# GD32G5x3 register map
File version: 1.0
CPU: CM33 r2p1, little endian, MPU, FPU, 4 interrupt priority bits
Registers are 32-bit, read-write, reset 0x0 unless marked. A register's access mark holds for its fields unless they carry their own. Offsets are from the block's base; [hi:lo] are bit positions; {n}, {i} and the like mark numbered series; 'fields as' and 'values as' point back to an identical list.

## DMAMUX — DMA request multiplexer
Base 0x40020800
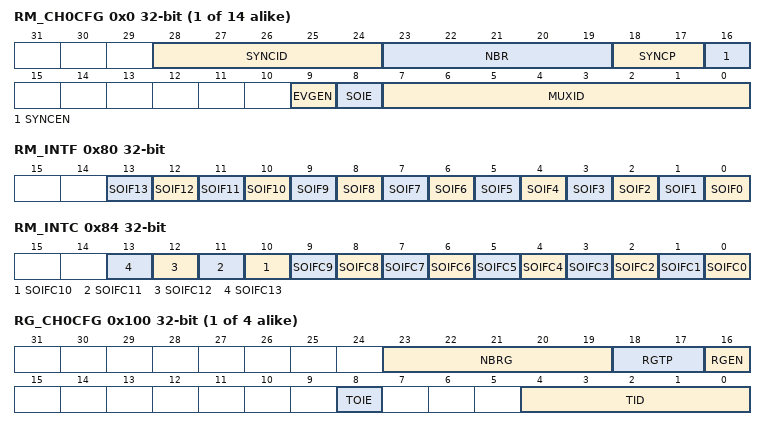
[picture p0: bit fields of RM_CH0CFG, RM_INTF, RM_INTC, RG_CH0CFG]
{0x0+4i} RM_CH{i}CFG (i=0..13) — Request multiplexer channel {i} configuration register
  [28:24] SYNCID — Synchronization input identification
  [23:19] NBR — Number of DMA requests to forward
  [18:17] SYNCP — Synchronization input polarity
  [16] SYNCEN — Synchronization enable
  [9] EVGEN — Event generation enable
  [8] SOIE — Synchronization overrun interrupt enable
  [7:0] MUXID — Multiplexer input identification
0x80 RM_INTF ro — Request multiplexer channel interrupt flag register
  [n] SOIF{n} (n=0..13) — Synchronization overrun event flag of request multiplexer channel {n}
0x84 RM_INTC wo — Request multiplexer channel interrupt flag clear register
  [n] SOIFC{n} (n=0..13) — Clear bit for synchronization overrun event flag of request multiplexer channel {n}
{0x100+4i} RG_CH{i}CFG (i=0..3) — Request generator channel {i} configuration register
  [23:19] NBRG — Number of DMA requests to be generated
  [18:17] RGTP — DMA request generator trigger polarity
  [16] RGEN — DMA request generator channel x enable
  [8] TOIE — Trigger overrun interrupt enable
  [4:0] TID — Trigger input identification
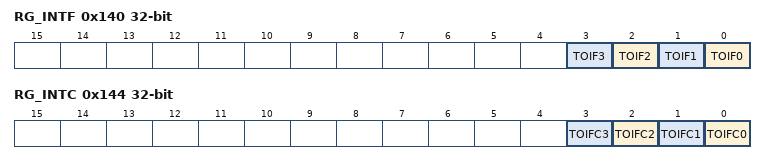
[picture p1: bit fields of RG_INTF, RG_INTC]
0x140 RG_INTF ro — Request generator interrupt flag register
  [n] TOIF{n} (n=0..3) — Trigger overrun event flag of request generator channel {n}
0x144 RG_INTC wo — Request generator interrupt flag clear register
  [n] TOIFC{n} (n=0..3) — Clear bit for trigger overrun event flag of request generator channel {n}

## EXMC — External memory controller
Base 0xA0000000
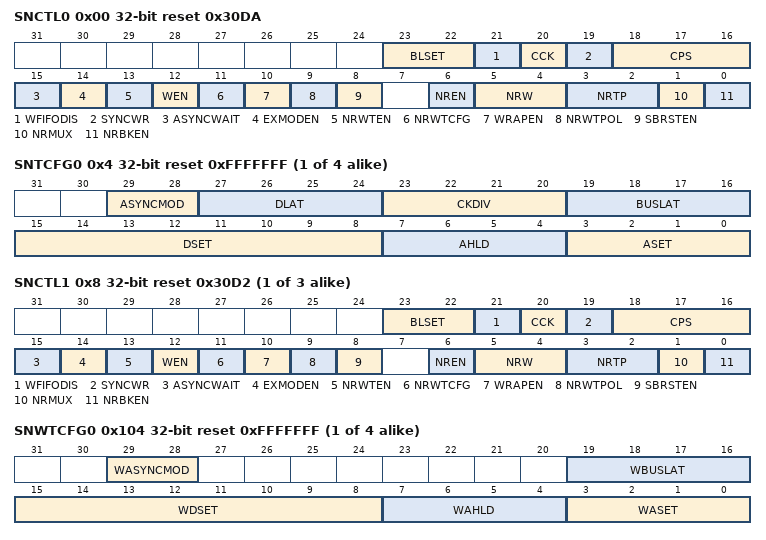
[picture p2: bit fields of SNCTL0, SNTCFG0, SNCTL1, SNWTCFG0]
0x00 SNCTL0 reset 0x30DA — SRAM/NOR Flash control registe 0
  [23:22] BLSET — NBL(Byte lane) setup time
  [21] WFIFODIS — Write FIFO disabled
  [20] CCK — Consecutive Clock
  [19] SYNCWR — Synchronous write
  [18:16] CPS — CRAM page size
  [15] ASYNCWAIT — Asynchronous wait
  [14] EXMODEN — Extended mode enable
  [13] NRWTEN — NWAIT signal enable
  [12] WEN — Write enable
  [11] NRWTCFG — NWAIT signal configuration, only work in synchronous mode
  [10] WRAPEN — Wrapped burst mode enable
  [9] NRWTPOL — NWAIT signal polarity
  [8] SBRSTEN — Synchronous burst enable
  [6] NREN — NOR Flash access enable
  [5:4] NRW — NOR region memory data bus width
  [3:2] NRTP — NOR region memory type
  [1] NRMUX — NOR region memory address/data multiplexing
  [0] NRBKEN — NOR region enable
{0x4+8i} SNTCFG{i} reset 0xFFFFFFF (i=0..3) — SRAM/NOR Flash timing configuration registe {i}
  [29:28] ASYNCMOD — Asynchronous access mode
  [27:24] DLAT — Data latency for NOR Flash
  [23:20] CKDIV — Synchronous clock divide ratio
  [19:16] BUSLAT — Bus latency
  [15:8] DSET — Data setup time
  [7:4] AHLD — Address hold time
  [3:0] ASET — Address setup time
{0x0+8i} SNCTL{i} reset 0x30D2 (i=1..3) — SRAM/NOR Flash control registe {i}
  fields as SNCTL0
0x84 SNSTAT ro reset 0x40 — SRAM/NOR flash status registers
  [6] FIFOEPT — FIFO empty flag
{0x104+8i} SNWTCFG{i} reset 0xFFFFFFF (i=0..3) — SRAM/NOR Flash write timing configuration registe {i}
  [29:28] WASYNCMOD — Asynchronous access mode
  [19:16] WBUSLAT — Bus latency
  [15:8] WDSET — Data setup time
  [7:4] WAHLD — Address hold time
  [3:0] WASET — Address setup time
{0x300+4i} SNLATDEC{i} (i=0..3) — SRAM/NOR flash data latency decrease register {i}
  [2:0] LATDEC — Data latency decrease for NOR Flash

## EXTI — External interrupt/event controller
Base 0x40010400
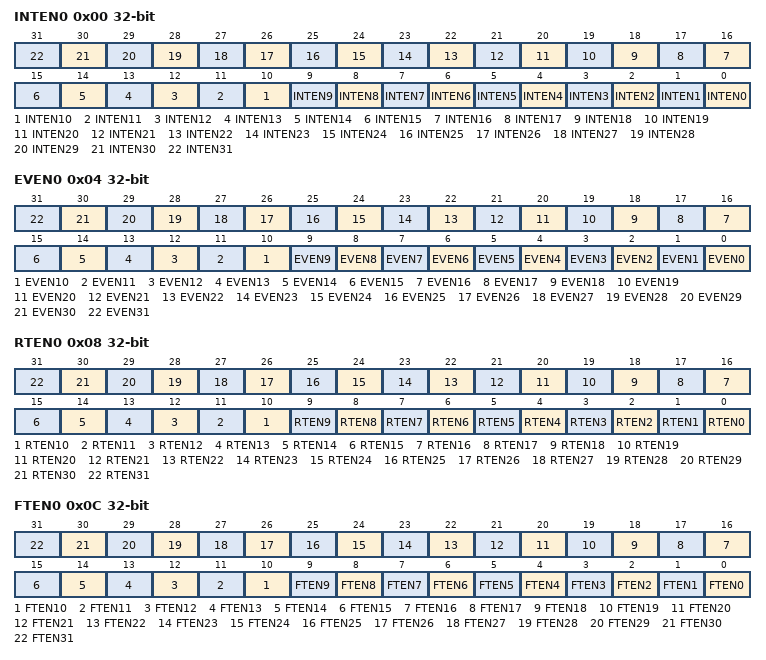
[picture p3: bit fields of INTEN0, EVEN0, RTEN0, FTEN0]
0x00 INTEN0 — Interrupt enable register 0
  [n] INTEN{n} (n=0..31) — Interrupt enable bit {n}
0x04 EVEN0 — Event enable register 0
  [n] EVEN{n} (n=0..31) — Event enable bit {n}
0x08 RTEN0 — Rising edge trigger enable register 0
  [n] RTEN{n} (n=0..31) — Rising edge trigger enable bit {n}
0x0C FTEN0 — Falling edge trigger enable register 0
  [n] FTEN{n} (n=0..31) — Falling edge trigger enable bit {n}
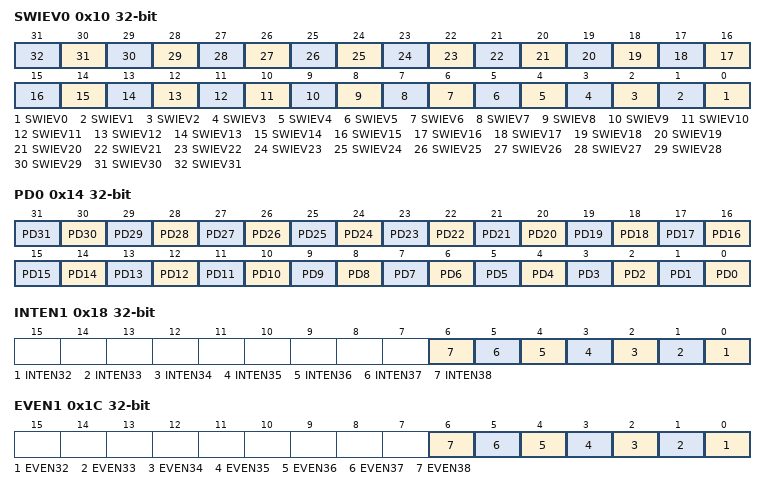
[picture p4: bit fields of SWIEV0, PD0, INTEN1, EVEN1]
0x10 SWIEV0 — Software interrupt event register 0
  [n] SWIEV{n} (n=0..31) — Interrupt/Event software trigger bit {n}
0x14 PD0 — Pending register 0
  [n] PD{n} (n=0..31) — Interrupt pending status bit {n}
0x18 INTEN1 — Interrupt enable register 1
  [n-32] INTEN{n} (n=32..38) — Interrupt enable bit {n-32}
0x1C EVEN1 — Event enable register 1
  [n-32] EVEN{n} (n=32..38) — Event enable bit {n-32}
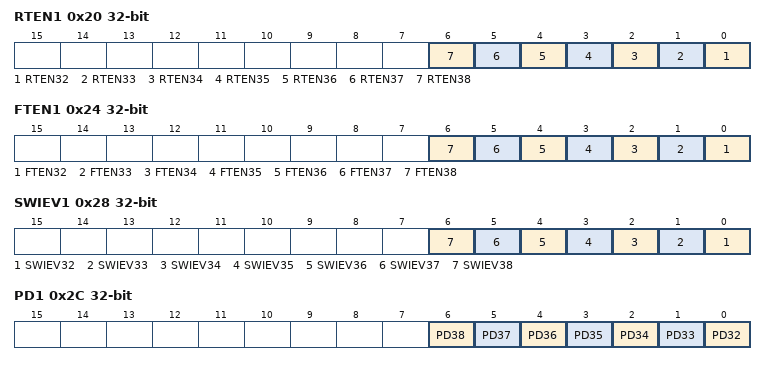
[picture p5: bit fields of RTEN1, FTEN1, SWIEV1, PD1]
0x20 RTEN1 — Rising edge trigger enable register 1
  [n-32] RTEN{n} (n=32..38) — Rising edge trigger enable {n-32}
0x24 FTEN1 — Falling edge trigger enable register 1
  [n-32] FTEN{n} (n=32..38) — Falling edge trigger enable {n-32}
0x28 SWIEV1 — Software interrupt event register 1
  [n-32] SWIEV{n} (n=32..38) — Interrupt / Event software trigger {n-32}
0x2C PD1 — Pending register 1
  [n-32] PD{n} (n=32..38) — Interrupt pending status {n-32}
